# ALL_DSS_RFBI register map
Vendor: Texas Instruments
Peripheral module from a debugger description file (folder am437x).
Registers are 32-bit, access not given, no defined reset value unless marked. A register's access mark holds for its fields unless they carry their own. Offsets are as the file gives them; lines under a group give offsets from that group; [hi:lo] are bit positions; {n}, {i} and the like mark numbered series; 'fields as' and 'values as' point back to an identical list; <NAME> marks a mode.

## ALL_DSS_RFBI
0x00 RFBI_REVISION ro — This Register contains the IP revision code
  [7:0] REV — IP Revision
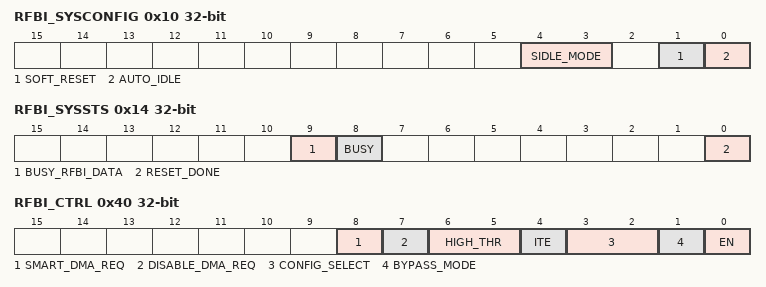
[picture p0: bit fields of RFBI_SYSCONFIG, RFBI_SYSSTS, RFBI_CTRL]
0x10 RFBI_SYSCONFIG rw — This Register allows control of various parameters of the Interconnect Interface
  [4:3] SIDLE_MODE — Slave interface power management, Idle req/ack control
    3=en_4_0x3 (3); 2=en_3_0x2 (Idle request is acknowledged based on the internal activity of the module); 1=en_2_0x1 (An idle request is never acknowledged); 0=en_1_0x0 (Idle request is acknowledged unconditionally)
  [1] SOFT_RESET — Software reset Sets this bit to 1 to trigger a module reset. [[br]]The bit is automatically reset by the hardware. [[br]]During reads, it always returns 0
    1=en_2_0x1 (The module is reset); 0=en_1_0x0 (Normal mode)
  [0] AUTO_IDLE — Internal clock gating strategy (interconnectL4 and display controller clock)
    1=en_2_0x1 (Automatic clock gating strategy is applied for the interconnect L4 clock and display controller clock, based on the interconnect interface and internal activity); 0=en_1_0x0 (Interconnect L4 clock and display controller clock are free-running.)
0x14 RFBI_SYSSTS ro — This register provides status information about the module, excluding the interrupt status information.
  [9] BUSY_RFBI_DATA — Data are pending to be processed from interconnect FIFO.
    1=en_2_0x1 (Data Pending); 0=en_1_0x0 (No Data Pending)
  [8] BUSY — L4 Interface busy status bit
    1=en_2_0x1 (The access to any of the following registers is stalled: RFBI_CMD, RFBI_DATA, RFBI_STATUS, RFBI_PARAM, RFBI_READ.); 0=en_1_0x0 (The access to the following register is not stalled: RFBI_CMD, RFBI_DATA, RFBI_STATUS, RFBI_PARAM, RFBI_READ)
  [0] RESET_DONE — Internal reset monitoring
    1=en_2_0x1 (Reset Completed); 0=en_1_0x0 (Internal module reset is on-going)
0x40 RFBI_CTRL rw — The control register allows configuration of the RFBI module
  [8] SMART_DMA_REQ — Smart DMA request
    1=en_2_0x1 (The dmareq is de-asserted after 2 clk cycles if it has been asserted for more than or equal to 2 clk cycles and MIdlereq is high in smart idle or no idle mode. No more burst requests will be given even if the space is available in the interconnect FIFO.); 0=en_1_0x0 (The dmareq is asserted and de-asserted depending on the interconnect FIFO space even if MIdlereq is high in smart idle/no-idle mode and the entire burst gets error responses from the module.)
  [7] DISABLE_DMA_REQ — Disable DMA request
    1=en_2_0x1 (The dmareq is disabled and the signal is not generated at all based on space in the interconnect FIFO. It stays high until the DISABLE DMAREQ is high even if there is space in the interconnect FIFO to take requests.); 0=en_1_0x0 (The dmareq is enabled and the signal is generated based on the space available and the request coming into the data register.)
  [6:5] HIGH_THR — Defines the interconnect FIFO high threshold used by HW to assert DMA request. [[br]]Used only if data written to RFBI_DATA are sent using system DMA
    2=en_3_0x2 (Size of the transfer of 16 words of 32-bit wide); 1=en_2_0x1 (Size of the transfer of 8 words of 32-bit wide); 0=en_1_0x0 (Size of the transfer of 4 words of 32-bit wide)
  [4] ITE — Internal Trigger
    1=en_2_0x1 (User sets the ITE bit to start the transfer, when H/W takes into account the bit, the H/W resets it); 0=en_1_0x0 (H/W waits for ITE bit to be set if in internal trigger mode for the configuration in use)
  [3:2] CONFIG_SELECT — Select the CS and configuration
    3=en_4_0x3 (CS0 and CS1 both selected (only the configuration for CS0 isused)); 2=en_3_0x2 (CS1 selected and configuration #1); 1=en_2_0x1 (CS0 selected and Configuration #0); 0=en_1_0x0 (No CS selected)
  [1] BYPASS_MODE
    1=en_2_0x1 (The bypass mode is selected); 0=en_1_0x0 (The bypass mode is not selected)
  [0] EN — Enable/Disable flag
    1=en_2_0x1 (Enable RFBI); 0=en_1_0x0 (Disable RFBI)
0x44 RFBI_PIXEL_CNT rw — The control register configures the RFBI pixel count value.
  [31:0] PIXEL_CNT — Pixel counter value The S/W indicates the number of pixels to transfer to the LCD panel frame buffer. [[br]]The value is set when the module is disabled. [[br]]During the transfer the HW decrements the register when a pixel has been sent to the RFB.
0x48 RFBI_LINE_NUMBER rw — The control register configures the number of lines to synchronize the beginning of the transfer.
  [10:0] LINE_NUMBER — Programmable line number Line number from 0 to 2^[[br]]11-1. [[br]]Number of HSYNC after the VSYNC occurs before the beginning of the transfer.
0x4C RFBI_CMD rw — The control register configures the RFBI command
  [15:0] CMD — Command Value 8/9/12/16 bit value depending on the parallel mode
0x50 RFBI_PARAM rw — The control register configures the RFBI parameter.
  [15:0] PARAM — Param Value 8/9/12/16 bit value depending on the parallel mode
0x54 RFBI_DATA rw — The control register configures the RFBI data.
  [31:0] DATA — Data value 12/16/18/24/2x16 bit value depending on the Data type
0x58 RFBI_READ rw — The control register configures the RFBI read
  [15:0] READ — Read Value 8/9/12/16 bit value depending on the parallel mode
0x5C RFBI_STS rw — The control register configures the RFBI status.
  [15:0] STS — Status value 8/9/12/16 bit value depending on the parallel mode
0x60 RFBI_CONFIG_0
0x64 RFBI_ONOFF_TIME_0
0x68 RFBI_CYCLE_TIME_0
{0x68+4i} RFBI_DATA_CYCLE{i}_0 (i=1..3)
0x78 RFBI_CONFIG_1
0x7C RFBI_ONOFF_TIME_1
0x80 RFBI_CYCLE_TIME_1
{0x80+4i} RFBI_DATA_CYCLE{i}_1 (i=1..3)
0x90 RFBI_VSYNC_WIDTH rw — The control register configures the RFBI VSYNC minimum pulse width
  [15:0] MIN_VSYNC_PULSE_WIDTH — Programmable min VSYNC pulse width Minimum VSYNC pulse width from 0 to 65535. [[br]]Number of L4 clock cycles to determine when VSYNC pulse occurs. [[br]]The values 0 and 1 are invalid.
0x94 RFBI_HSYNC_WIDTH rw — The control register configures the RFBI HSYNC minimum pulse width.
  [15:0] MIN_HSYNC_PULSE_WIDTH — Programmable min HSYNC pulse width Minimum HSYNC pulse width from 0 to 65535. [[br]]Number of L4 clock cycles to determine when HSYNC pulse occurs. [[br]]The values 0 and 1 are invalid.
